# spi_reva_me30 register map
Registers are read-write, no defined reset value unless marked. A register's access mark holds for its fields unless they carry their own. Offsets are from the block's base; lines under a group give offsets from that group; [hi:lo] are bit positions; {n}, {i} and the like mark numbered series; 'fields as' and 'values as' point back to an identical list; <NAME> marks a mode.

## Memory map
0x40046000 SPI size 0x1000 — SPI peripheral.

## Interrupts
16 SPI0 (SPI)

## SPI — SPI peripheral.
Base 0x40046000
0x00 FIFO32 32-bit — Register for reading and writing the FIFO.
  [31:0] DATA — Read to pull from RX FIFO, write to put into TX FIFO.
{0x0+2i} FIFO16[{i}] (i=0..1) 16-bit (alternate view of FIFO32) — Register for reading and writing the FIFO.
  [15:0] DATA — Read to pull from RX FIFO, write to put into TX FIFO.
{0x0+i} FIFO8[{i}] (i=0..3) 8-bit (alternate view of FIFO32) — Register for reading and writing the FIFO.
  [7:0] DATA — Read to pull from RX FIFO, write to put into TX FIFO.
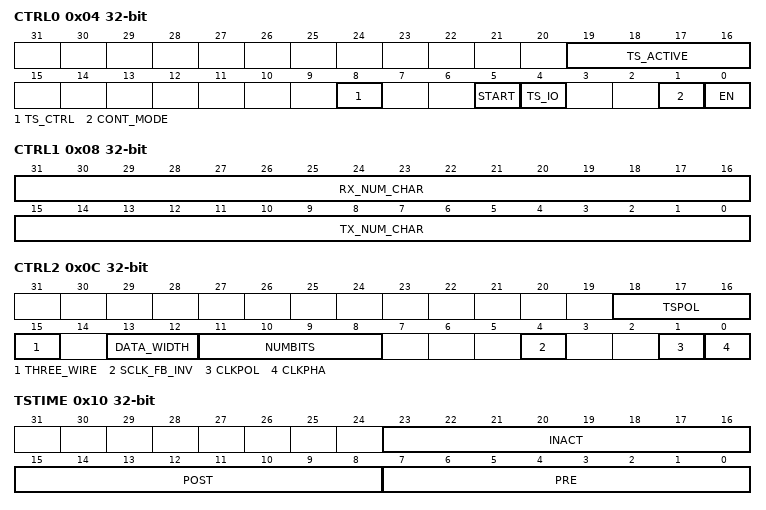
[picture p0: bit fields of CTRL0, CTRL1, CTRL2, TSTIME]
0x04 CTRL0 — Register for controlling SPI peripheral.
  [19:16] TS_ACTIVE — Target Select, when in Controller mode selects which Target devices are selected. More than one Target device can be selected.
    1=TS0 (TS0 is selected.); 2=TS1 (TS1 is selected.); 4=TS2 (TS2 is selected.)
  [8] TS_CTRL — Start Select Control. Used in Controller mode to control the behavior of the Target Select signal at the end of a transaction.
    0=DEASSERT (SPI De-asserts Target Select at the end of a transaction.); 1=ATSERT (SPI leaves Target Select asserted at the end of a transaction.)
  [5] START — Start Transmit.
    1=start (Controller Initiates a transaction, this bit is self clearing when transactions are done. If a transaction cimpletes, and the TX FIFO is empty, the Controller halts, if a transaction completes, and the TX FIFO is not empty, the Controller initiates another transaction.)
  [4] TS_IO — Target Select 0, IO direction, to support Multi-Controller mode,Target Select 0 can be input in Controller mode. This bit has no effect in target mode.
    0=output (Target select 0 is output.); 1=input (Target Select 0 is input, only valid if MMEN=1.)
  [1] CONT_MODE — Controller Mode Enable.
    0=dis (SPI is Target mode.); 1=en (SPI is Controller mode.)
  [0] EN — SPI Enable.
    0=dis (SPI is disabled.); 1=en (SPI is enabled.)
0x08 CTRL1 — Register for controlling SPI peripheral.
  [31:16] RX_NUM_CHAR — Nubmer of Characters to receive.
  [15:0] TX_NUM_CHAR — Nubmer of Characters to transmit.
0x0C CTRL2 — Register for controlling SPI peripheral.
  [18:16] TSPOL — Target Select Polarity, each Target Select can have unique polarity.
    1=TS0_high (TS0 active high.); 2=TS1_high (TS1 active high.); 4=TS2_high (TS2 active high.)
  [15] THREE_WIRE — Three Wire mode. MOSI/MISO pin(s) shared. Only Mono mode suports Four-Wire.
    0=dis (Use four wire mode (Mono only).); 1=en (Use three wire mode.)
  [13:12] DATA_WIDTH — SPI Data width.
    0=Mono (1 data pin.); 1=Dual (2 data pins.); 2=Quad (4 data pins.)
  [11:8] NUMBITS — Number of Bits per character.
    0=16 bits per character; {v}={v} bits per character (v=1..15)
  [4] SCLK_FB_INV — Clock Polarity.
    0=Normal Clock. Use when in SPI Mode 0 and Mode 1; 1=Inverted Clock. Use when in SPI Mode 2 and Mode 3
  [1] CLKPOL — Clock Polarity.
    values as SCLK_FB_INV
  [0] CLKPHA — Clock Phase.
    0=Rising_Edge (Data Sampled on clock rising edge. Use when in SPI Mode 0 and Mode 2); 1=Falling_Edge (Data Sampled on clock falling edge. Use when in SPI Mode 1 and Mode 3)
0x10 TSTIME — Register for controlling SPI peripheral/Target Select Timing.
  [23:16] INACT — Target Select Inactive delay.
    0=256 system clocks between transactions
  [15:8] POST — Target Select Post delay 2.
    0=256 system clocks between last serial clock edge and TS inactive
  [7:0] PRE — Target Select Pre delay 1.
    0=256 system clocks between TS active and first serial clock edge
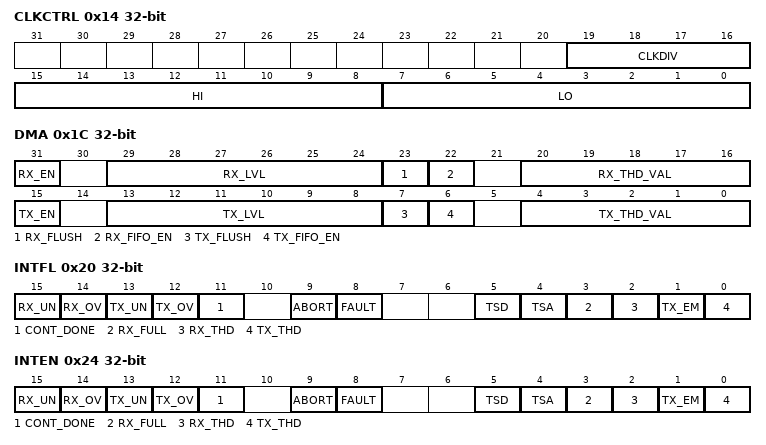
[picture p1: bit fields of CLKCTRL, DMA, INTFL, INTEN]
0x14 CLKCTRL — Register for controlling SPI clock rate.
  [19:16] CLKDIV — System Clock scale factor. Scales the AMBA clock by 2^SCALE before generating serial clock.
  [15:8] HI — High duty cycle control. In timer mode, reload[15:8].
    0=Dis (Duty cycle control of serial clock generation is disabled.)
  [7:0] LO — Low duty cycle control. In timer mode, reload[7:0].
    values as HI
0x1C DMA — Register for controlling DMA.
  [31] RX_EN — RX DMA Enable.
    0=dis (RX DMA requests are disabled, any pending DMA requests are cleared.); 1=en (RX DMA requests are enabled.)
  [29:24] RX_LVL ro — Count of entries in RX FIFO.
  [23] RX_FLUSH — Clear RX FIFO, clear is accomplished by resetting the read and write pointers. This should be done when FIFO is not being accessed on the SPI side.
    1=CLEAR (Clear the Receive FIFO, clears any pending RX FIFO status.)
  [22] RX_FIFO_EN — Receive FIFO enabled for SPI transactions.
    0=DIS (Receive FIFO is not enabled.); 1=en (Receive FIFO is enabled.)
  [20:16] RX_THD_VAL — Receive FIFO level that will trigger a DMA request, also level for threshold status. When RX FIFO has more than this many bytes, the associated events and conditions are triggered.
  [15] TX_EN — TX DMA Enable.
    0=DIS (TX DMA requests are disabled, andy pending DMA requests are cleared.); 1=en (TX DMA requests are enabled.)
  [13:8] TX_LVL ro — Count of entries in TX FIFO.
  [7] TX_FLUSH — Clear TX FIFO, clear is accomplished by resetting the read and write pointers. This should be done when FIFO is not being accessed on the SPI side. .
    1=CLEAR (Clear the Transmit FIFO, clears any pending TX FIFO status.)
  [6] TX_FIFO_EN — Transmit FIFO enabled for SPI transactions.
    0=dis (Transmit FIFO is not enabled.); 1=en (Transmit FIFO is enabled.)
  [4:0] TX_THD_VAL — Transmit FIFO level that will trigger a DMA request, also level for threshold status. When TX FIFO has fewer than this many bytes, the associated events and conditions are triggered.
0x20 INTFL — Register for reading and clearing interrupt flags. All bits are write 1 to clear.
  [all] fields
    1=clear (Flag is set when value read is 1. Write 1 to clear this flag.)
  [15] RX_UN — Receive FIFO Underrun, set when the AMBA side attempts to read data from an empty receive FIFO.
  [14] RX_OV — Receive FIFO Overrun, set when the SPI side attempts to write to a full receive FIFO.
  [13] TX_UN — Transmit FIFO Underrun, set when the SPI side attempts to read data from an empty transmit FIFO.
  [12] TX_OV — Transmit FIFO Overrun, set when the AMBA side attempts to write data to a full transmit FIFO.
  [11] CONT_DONE — Controller Done, set when SPI Controller has completed any transactions.
  [9] ABORT — Target Abort Detected.
  [8] FAULT — Multi-Controller Mode Fault.
  [5] TSD — Target Select Deasserted.
  [4] TSA — Target Select Asserted.
  [3] RX_FULL — RX FIFO FULL.
  [2] RX_THD — RX FIFO Threshold Crossed.
  [1] TX_EM — TX FIFO Empty.
  [0] TX_THD — TX FIFO Threshold Crossed.
0x24 INTEN — Register for enabling interrupts.
  [all] fields
    0=dis (Interrupt is disabled.); 1=en (Interrupt is enabled.)
  [15] RX_UN — Receive FIFO Underrun interrupt enable.
  [14] RX_OV — Receive FIFO Overrun interrupt enable.
  [13] TX_UN — Transmit FIFO Underrun interrupt enable.
  [12] TX_OV — Transmit FIFO Overrun interrupt enable.
  [11] CONT_DONE — Controller Done interrupt enable.
  [9] ABORT — Target Abort Detected interrupt enable.
  [8] FAULT — Multi-Controller Mode Fault interrupt enable.
  [5] TSD — Target Select Deasserted interrupt enable.
  [4] TSA — Target Select Asserted interrupt enable.
  [3] RX_FULL — RX FIFO FULL interrupt enable.
  [2] RX_THD — RX FIFO Threshold Crossed interrupt enable.
  [1] TX_EM — TX FIFO Empty interrupt enable.
  [0] TX_THD — TX FIFO Threshold interrupt enable.
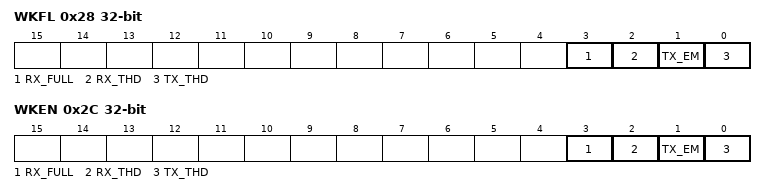
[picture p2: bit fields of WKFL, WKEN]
0x28 WKFL — Register for wake up flags. All bits in this register are write 1 to clear.
  [all] fields
    values as the fields of INTFL
  [3] RX_FULL — Wake on RX FIFO Full.
  [2] RX_THD — Wake on RX FIFO Threshold Crossed.
  [1] TX_EM — Wake on TX FIFO Empty.
  [0] TX_THD — Wake on TX FIFO Threshold Crossed.
0x2C WKEN — Register for wake up enable.
  [all] fields
    0=dis (Wakeup source disabled.); 1=en (Wakeup source enabled.)
  [3] RX_FULL — Wake on RX FIFO Full Enable.
  [2] RX_THD — Wake on RX FIFO Threshold Crossed Enable.
  [1] TX_EM — Wake on TX FIFO Empty Enable.
  [0] TX_THD — Wake on TX FIFO Threshold Crossed Enable.
0x30 STATUS ro — SPI Status register.
  [0] BUSY — SPI active status. In Controller mode, set when transaction starts, cleared when last bit of last character is acted upon and Target Select de-assertion would occur. In Target mode, set when Target Select is asserted, cleared when Target Select is de-asserted. Not used in Timer mode.
    0=not (SPI not active.); 1=active (SPI active.)
